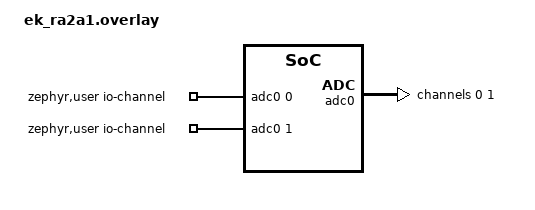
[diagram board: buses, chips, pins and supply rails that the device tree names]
/*
 * Copyright (c) 2025 Renesas Electronics Corporation
 *
 * SPDX-License-Identifier: Apache-2.0
 */

/ {
	zephyr,user {
		io-channels = <&adc0 0>, <&adc0 1>;
	};
};

&pinctrl {
	adc0_default: adc0_default {
		group1 {
			/* input */
			psels = <RA_PSEL(RA_PSEL_ADC, 5, 0)>,
				<RA_PSEL(RA_PSEL_ADC, 5, 1)>;
			renesas,analog-enable;
		};
	};
};

&adc0 {
	pinctrl-0 = <&adc0_default>;
	pinctrl-names = "default";
	status = "okay";
	#address-cells = <1>;
	#size-cells = <0>;
	interrupts = <31 1>;
	interrupt-names = "scanend";

	/*
	 * Channel 0 is used in single ended mode, with 15 bit resolution
	 */
	channel@0 {
		reg = <0>;
		zephyr,gain = "ADC_GAIN_1";
		zephyr,reference = "ADC_REF_EXTERNAL0";
		zephyr,resolution = <15>;
		zephyr,acquisition-time = <0>;
		zephyr,vref-mv = <3300>;
	};

	/*
	 * Channel 1 is used in single ended mode, with 15 bit resolution
	 */
	channel@1 {
		reg = <1>;
		zephyr,gain = "ADC_GAIN_1";
		zephyr,reference = "ADC_REF_EXTERNAL0";
		zephyr,resolution = <15>;
		zephyr,acquisition-time = <0>;
		zephyr,vref-mv = <3300>;
	};
};
